# CORE_CM_CORE register map
Vendor: Texas Instruments
Peripheral module from a debugger description file (folder omap5430_ES2_PUBLIC).
Registers are 32-bit, access per field, reset 0x30000 unless marked. A register's access mark holds for its fields unless they carry their own. Offsets are as the file gives them; lines under a group give offsets from that group; [hi:lo] are bit positions; {n}, {i} and the like mark numbered series; 'fields as' and 'values as' point back to an identical list; <NAME> marks a mode.

## CORE_CM_CORE
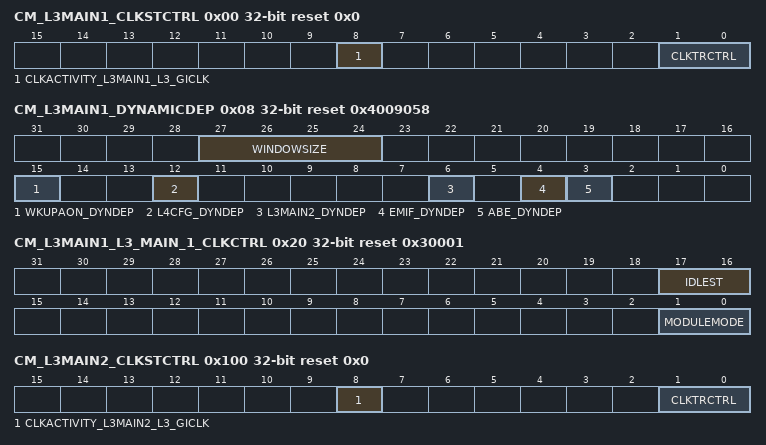
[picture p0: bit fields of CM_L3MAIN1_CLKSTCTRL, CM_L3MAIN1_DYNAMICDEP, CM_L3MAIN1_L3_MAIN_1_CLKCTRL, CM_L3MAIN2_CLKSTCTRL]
0x00 CM_L3MAIN1_CLKSTCTRL reset 0x0 — This register enables the domain power state transition. It controls the HW supervised domain power state transition between ON-ACTIVE and ON-INACTIVE states. It also holds 1 status bit per clock input of the domain.
  [8] CLKACTIVITY_L3MAIN1_L3_GICLK ro — This field indicates the state of the L3MAIN1_L3_GICLK clock in the domain. [warm reset insensitive]
    0=Inact (Corresponding clock is definitely gated); 1=Act (Corresponding clock is running or gating/ungating transition is on-going)
  [1:0] CLKTRCTRL rw — Controls the clock state transition of the L3_MAIN1 clock domain.
    0=NO_SLEEP (NO_SLEEP: Sleep transition cannot be initiated. Wakeup transition may however occur.); 3=HW_AUTO (HW_AUTO: Automatic transition is enabled. Sleep and wakeup transition are based upon hardware conditions.)
0x08 CM_L3MAIN1_DYNAMICDEP reset 0x4009058 — This register controls the dynamic domain depedencies from L3_MAIN1 domain towards 'target' domains. It is relevant only for domain having INTRCONN master port(s).
  [27:24] WINDOWSIZE rw — Size of sliding window used to monitor INTRCONN interface activity for determination of auto-sleep feature. Time unit defined byCM_DYN_DEP_PRESCAL register.
  [15] WKUPAON_DYNDEP ro — Dynamic dependency towards WKUPAON clock domain Read 1: Dependency is enabled
  [12] L4CFG_DYNDEP ro — Dynamic dependency towards L4_CFG clock domain
    1=Enabled (Dependency is enabled)
  [6] L3MAIN2_DYNDEP ro — Dynamic dependency towards L3_MAIN2 clock domain
    1=Enabled (Dependency is enabled)
  [4] EMIF_DYNDEP ro — Dynamic dependency towards EMIF clock domain
    1=Enabled (Dependency is enabled)
  [3] ABE_DYNDEP ro — Dynamic dependency towards ABE clock domain
    1=Enabled (Dependency is enabled)
0x20 CM_L3MAIN1_L3_MAIN_1_CLKCTRL ro reset 0x30001 — This register manages the L3_MAIN1 clocks.
  [17:16] IDLEST — Module idle status. [warm reset insensitive]
    0=Func (Module is fully functional, including INTRCONN); 1=Trans (Module is performing transition: wakeup, or sleep, or sleep abortion); 2=Idle (Module is in Idle mode (only INTRCONN part). It is functional if using separate functional clock); 3=Disable (Module is disabled and cannot be accessed)
  [1:0] MODULEMODE — Control the way mandatory clocks are managed.
    1=AUTO (Module is managed automatically by HW according to clock domain transition. A clock domain sleep transition put module into idle. A wakeup domain transition put it back into function. If[1:0] CLKTRCTRL = 0x3, any INTRCONN access to module is always granted. Module clocks may be gated according to the clock domain state.)
0x100 CM_L3MAIN2_CLKSTCTRL reset 0x0 — This register enables the domain power state transition. It controls the HW supervised domain power state transition between ON-ACTIVE and ON-INACTIVE states. It also holds 1 status bit per clock input of the domain.
  [8] CLKACTIVITY_L3MAIN2_L3_GICLK ro — This field indicates the state of the L3MAIN2_L3_GICLK clock in the domain. [warm reset insensitive]
    values as CM_L3MAIN1_CLKSTCTRL.CLKACTIVITY_L3MAIN1_L3_GICLK
  [1:0] CLKTRCTRL rw — Controls the clock state transition of the L3_MAIN2 clock domain.
    values as CM_L3MAIN1_CLKSTCTRL.CLKTRCTRL
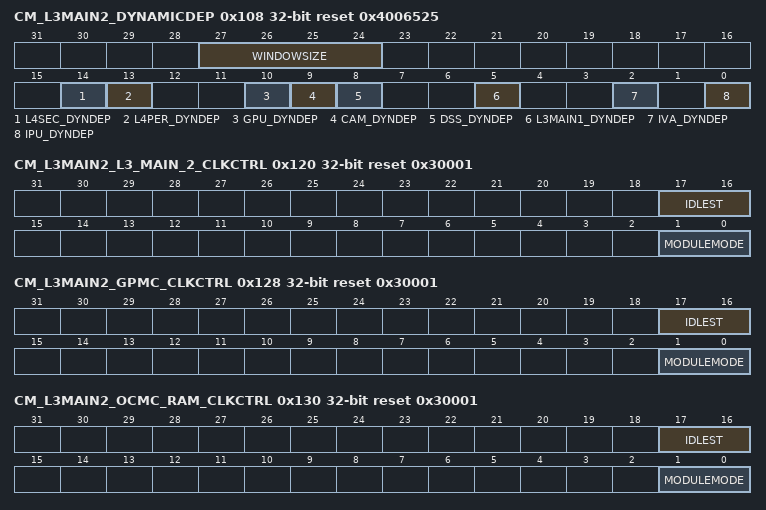
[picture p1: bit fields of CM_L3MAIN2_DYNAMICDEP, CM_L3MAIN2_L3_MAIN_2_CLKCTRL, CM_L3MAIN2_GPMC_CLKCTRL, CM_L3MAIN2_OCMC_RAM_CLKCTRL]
0x108 CM_L3MAIN2_DYNAMICDEP reset 0x4006525 — This register controls the dynamic domain dependencies from L3_MAIN2 domain towards 'target' domains. It is relevant only for domain having INTERCONN master port(s).
  [27:24] WINDOWSIZE rw — Size of sliding window used to monitor INTRCONN interface activity for determination of auto-sleep feature. Time unit defined byCM_DYN_DEP_PRESCAL register.
  [14] L4SEC_DYNDEP ro — Dynamic dependency towards L4SEC clock domain
    1=Dependency_is_enabled
  [13] L4PER_DYNDEP ro — Dynamic dependency towards L4_PER clock domain
    1=Enabled (Dependency is enabled)
  [10] GPU_DYNDEP ro — Dynamic dependency towards GPU clock domain
    1=Enabled (Dependency is enabled)
  [9] CAM_DYNDEP ro — Dynamic dependency towards CAM clock domain
    0=Disabled (Dependency is disabled)
  [8] DSS_DYNDEP ro — Dynamic dependency towards DSS clock domain
    1=Enabled (Dependency is enabled)
  [5] L3MAIN1_DYNDEP ro — Dynamic dependency towards L3_MAIN1 clock domain
    1=Enabled (Dependency is enabled)
  [2] IVA_DYNDEP ro — Dynamic dependency towards IVA clock domain
    1=Enabled (Dependency is enabled)
  [0] IPU_DYNDEP ro — Dynamic dependency towards IPU clock domain
    1=Enabled (Dependency is enabled)
0x120 CM_L3MAIN2_L3_MAIN_2_CLKCTRL ro reset 0x30001 — This register manages the L3_MAIN2 clocks.
  [17:16] IDLEST — Module idle status. [warm reset insensitive]
    values as CM_L3MAIN1_L3_MAIN_1_CLKCTRL.IDLEST
  [1:0] MODULEMODE — Control the way mandatory clocks are managed.
    1=AUTO (Module is managed automatically by HW according to clock domain transition. A clock domain sleep transition put module into idle. A wakeup domain transition put it back into function. If[1:0] CLKTRCTRL = 0x3 (HW_AUTO), any INTRCONN access to module is always granted. Module clocks may be gated according to the clock domain state.)
0x128 CM_L3MAIN2_GPMC_CLKCTRL reset 0x30001 — This register manages the GPMC clocks.
  [17:16] IDLEST ro — Module idle status. [warm reset insensitive]
    values as CM_L3MAIN1_L3_MAIN_1_CLKCTRL.IDLEST
  [1:0] MODULEMODE rw — Control the way mandatory clocks are managed.
    0=DISABLED (Module is temporarily disabled by SW. Interconnect access to module are stalled. Can be used to change timing parameter of GPMC module.); 1=RESERVED (Module is managed automatically by HW according to clock domain transition. A clock domain sleep transition put module into idle. A wakeup domain transition put it back into function. If[1:0] CLKTRCTRL = 0x3 (HW_AUTO), any INTRCONN access to module is always granted. Module clocks may be gated according to the clock domain state.)
0x130 CM_L3MAIN2_OCMC_RAM_CLKCTRL ro reset 0x30001 — This register manages the OCMC_RAM clocks.
  fields as CM_L3MAIN2_L3_MAIN_2_CLKCTRL
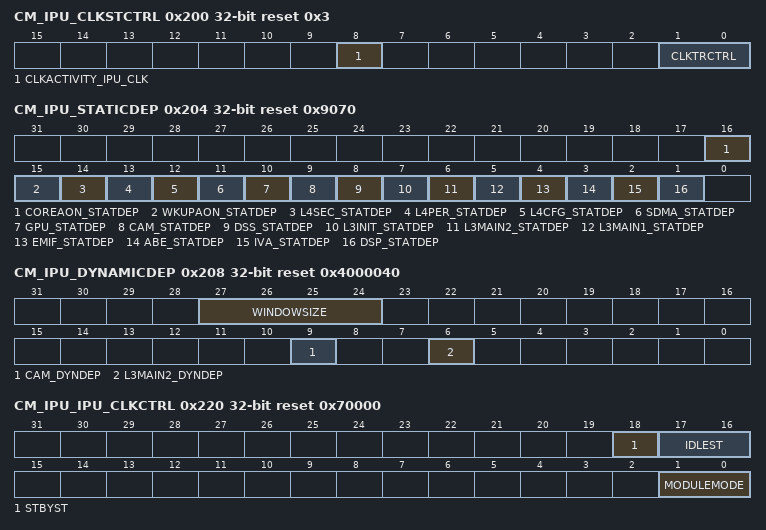
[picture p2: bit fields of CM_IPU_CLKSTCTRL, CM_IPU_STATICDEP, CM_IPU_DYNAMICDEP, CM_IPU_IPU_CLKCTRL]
0x200 CM_IPU_CLKSTCTRL reset 0x3 — This register enables the domain power state transition. It controls the HW supervised domain power state transition between ON-ACTIVE and ON-INACTIVE states. It also holds 1 status bit per clock input of the domain.
  [8] CLKACTIVITY_IPU_CLK ro — This field indicates the state of the IPU_CLK clock in the domain. [warm reset insensitive]
    0=Corresponding_clock_is_definitely_gated; 1=CLKACTIVITY_IPU_CLK_1_r (Corresponding clock is running or gating/ungating transition is on-going)
  [1:0] CLKTRCTRL rw — Controls the clock state transition of the IPU clock domain.
    0=NO_SLEEP (NO_SLEEP: Sleep transition cannot be initiated. Wakeup transition may however occur.); 1=SW_SLEEP (SW_SLEEP: Start a software forced sleep transition on the domain.); 2=SW_WKUP (SW_WKUP: Start a software forced wake-up transition on the domain.); 3=HW_AUTO (HW_AUTO: Automatic transition is enabled. Sleep and wakeup transition are based upon hardware conditions.)
0x204 CM_IPU_STATICDEP reset 0x9070 — This register controls the static domain dependencies from IPU domain towards 'target' domains. It is relevant only for domain having system initiator(s).
  [16] COREAON_STATDEP ro — Static dependency towards COREAON clock domain
    0=Disabled (Dependency is disabled)
  [15] WKUPAON_STATDEP rw — Static dependency towards WKUPAON clock domain
    0=Disabled (Dependency is disabled); 1=Enabled (Dependency is enabled)
  [14] L4SEC_STATDEP rw — Static dependency towards L4SEC clock domain
    0=Dependency_is_disabled; 1=Dependency_is_enabled
  [13] L4PER_STATDEP rw — Static dependency towards L4_PER clock domain
    values as WKUPAON_STATDEP
  [12] L4CFG_STATDEP rw — Static dependency towards L4_CFG clock domain
    values as WKUPAON_STATDEP
  [11] SDMA_STATDEP ro — Static dependency towards DMA_SYSTEM clock domain
    0=Disabled (Dependency is disabled)
  [10] GPU_STATDEP rw — Static dependency towards GPU clock domain
    values as WKUPAON_STATDEP
  [9] CAM_STATDEP ro — Static dependency towards CAM clock domain
    0=Disabled (Dependency is disabled)
  [8] DSS_STATDEP rw — Static dependency towards DSS clock domain
    values as WKUPAON_STATDEP
  [7] L3INIT_STATDEP rw — Static dependency towards L3INIT clock domain
    values as WKUPAON_STATDEP
  [6] L3MAIN2_STATDEP rw — Static dependency towards L3_MAIN2 clock domain
    values as WKUPAON_STATDEP
  [5] L3MAIN1_STATDEP rw — Static dependency towards L3_MAIN1 clock domain
    values as WKUPAON_STATDEP
  [4] EMIF_STATDEP rw — Static dependency towards EMIF clock domain
    values as WKUPAON_STATDEP
  [3] ABE_STATDEP rw — Static dependency towards ABE clock domain
    values as WKUPAON_STATDEP
  [2] IVA_STATDEP rw — Static dependency towards IVA clock domain
    values as WKUPAON_STATDEP
  [1] DSP_STATDEP rw — Static dependency towards DSP clock domain
    values as WKUPAON_STATDEP
0x208 CM_IPU_DYNAMICDEP reset 0x4000040 — This register controls the dynamic domain depedencies from IPU domain towards 'target' domains. It is relevant only for domain having INTRCONN master port(s).
  [27:24] WINDOWSIZE rw — Size of sliding window used to monitor INTRCONN interface activity for determination of auto-sleep feature. Time unit defined byCM_DYN_DEP_PRESCAL register.
  [9] CAM_DYNDEP ro — Dynamic dependency towards CAM clock domain
    0=Disabled (Dependency is disabled)
  [6] L3MAIN2_DYNDEP ro — Dynamic dependency towards L3_MAIN2 clock domain
    1=Enabled (Dependency is enabled)
0x220 CM_IPU_IPU_CLKCTRL reset 0x70000 — This register manages the IPU clocks.
  [18] STBYST ro — Module standby status. [warm reset insensitive]
    0=Func (Module is functional (not in standby)); 1=Standby (Module is in standby)
  [17:16] IDLEST ro — Module idle status. [warm reset insensitive]
    values as CM_L3MAIN1_L3_MAIN_1_CLKCTRL.IDLEST
  [1:0] MODULEMODE rw — Control the way mandatory clocks are managed.
    0=DISABLED (Module is disable by SW. Any INTRCONN access to module results in an error, except if resulting from a module wakeup (asynchronous wakeup).); 1=RESERVED (Module is managed automatically by HW according to clock domain transition. A clock domain sleep transition put module into idle. A wakeup domain transition put it back into function. If[1:0] CLKTRCTRL = 0x3 (HW_AUTO), any INTRCONN access to module is always granted. Module clocks may be gated according to the clock domain state.)
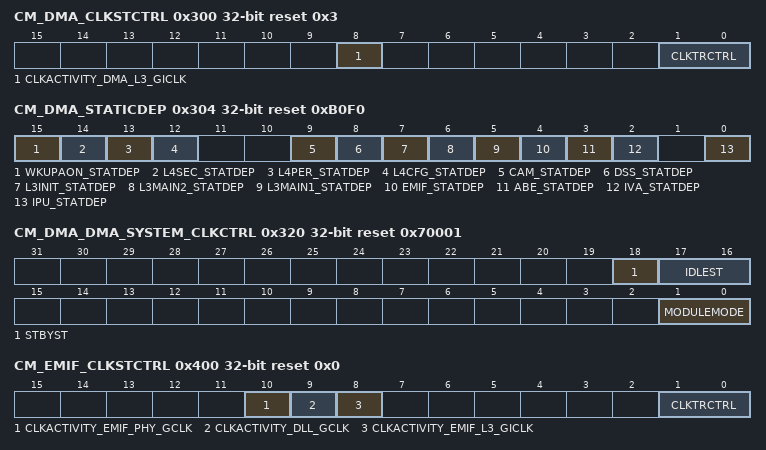
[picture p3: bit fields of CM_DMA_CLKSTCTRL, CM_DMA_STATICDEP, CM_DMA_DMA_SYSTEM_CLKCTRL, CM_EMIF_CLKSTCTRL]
0x300 CM_DMA_CLKSTCTRL reset 0x3 — This register enables the domain power state transition. It controls the HW supervised domain power state transition between ON-ACTIVE and ON-INACTIVE states. It also holds 1 status bit per clock input of the domain.
  [8] CLKACTIVITY_DMA_L3_GICLK ro — This field indicates the state of the L3_DMA_GICLK clock in the domain. [warm reset insensitive]
    values as CM_L3MAIN1_CLKSTCTRL.CLKACTIVITY_L3MAIN1_L3_GICLK
  [1:0] CLKTRCTRL rw — Controls the clock state transition of the DMA_SYSTEM clock domain.
    0=NO_SLEEP (NO_SLEEP: Sleep transition cannot be initiated. Wakeup transition may however occur.); 2=SW_WKUP (SW_WKUP: Start a software forced wake-up transition on the domain.); 3=HW_AUTO (HW_AUTO: Automatic transition is enabled. Sleep and wakeup transition are based upon hardware conditions.)
0x304 CM_DMA_STATICDEP reset 0xB0F0 — This register controls the static domain dependencies from DMA_SYSTEM domain towards 'target' domains. It is relevant only for domain having system initiator(s).
  [15] WKUPAON_STATDEP rw — Static dependency towards WKUPAON clock domain
    values as CM_IPU_STATICDEP.WKUPAON_STATDEP
  [14] L4SEC_STATDEP rw — Static dependency towards L4SEC clock domain
    0=Dependency_is_disabled; 1=Dependency_is_enabled
  [13] L4PER_STATDEP rw — Static dependency towards L4_PER clock domain
    values as CM_IPU_STATICDEP.WKUPAON_STATDEP
  [12] L4CFG_STATDEP rw — Static dependency towards L4_CFG clock domain
    values as CM_IPU_STATICDEP.WKUPAON_STATDEP
  [9] CAM_STATDEP ro — Static dependency towards CAM clock domain
    0=Disabled (Dependency is disabled)
  [8] DSS_STATDEP rw — Static dependency towards DSS clock domain
    values as CM_IPU_STATICDEP.WKUPAON_STATDEP
  [7] L3INIT_STATDEP rw — Static dependency towards L3INIT clock domain
    values as CM_IPU_STATICDEP.WKUPAON_STATDEP
  [6] L3MAIN2_STATDEP ro — Static dependency towards L3_MAIN2 clock domain
    1=Enabled (Dependency is enabled)
  [5] L3MAIN1_STATDEP rw — Static dependency towards L3_MAIN1 clock domain
    values as CM_IPU_STATICDEP.WKUPAON_STATDEP
  [4] EMIF_STATDEP rw — Static dependency towards EMIF clock domain
    values as CM_IPU_STATICDEP.WKUPAON_STATDEP
  [3] ABE_STATDEP rw — Static dependency towards ABE clock domain
    values as CM_IPU_STATICDEP.WKUPAON_STATDEP
  [2] IVA_STATDEP rw — Static dependency towards IVA clock domain
    values as CM_IPU_STATICDEP.WKUPAON_STATDEP
  [0] IPU_STATDEP rw — Static dependency towards IPU clock domain
    values as CM_IPU_STATICDEP.WKUPAON_STATDEP
0x308 CM_DMA_DYNAMICDEP ro reset 0x0 — This register controls the dynamic domain depedencies from DMA_SYSTEM domain towards 'target' domains. It is relevant only for domain having INTRCONN master port(s).
  [6] L3MAIN2_DYNDEP — Dynamic dependency towards L3_MAIN2 clock domain
    0=Disabled (Dependency is disabled)
0x320 CM_DMA_DMA_SYSTEM_CLKCTRL ro reset 0x70001 — This register manages the DMA_SYSTEM clocks.
  [18] STBYST — Module standby status. [warm reset insensitive]
    values as CM_IPU_IPU_CLKCTRL.STBYST
  [17:16] IDLEST — Module idle status. [warm reset insensitive]
    values as CM_L3MAIN1_L3_MAIN_1_CLKCTRL.IDLEST
  [1:0] MODULEMODE — Control the way mandatory clocks are managed.
    values as CM_L3MAIN2_L3_MAIN_2_CLKCTRL.MODULEMODE
0x400 CM_EMIF_CLKSTCTRL reset 0x0 — This register enables the domain power state transition. It controls the HW supervised domain power state transition between ON-ACTIVE and ON-INACTIVE states. It also hold one status bit per clock input of the domain.
  [10] CLKACTIVITY_EMIF_PHY_GCLK ro — This field indicates the state of the EMIF_PHY_GCLK clock in the domain. [warm reset insensitive]
    1=Act (Corresponding clock is running or gating/ungating transition is on-going); 0=Inact (Corresponding clock is definitely gated)
  [9] CLKACTIVITY_DLL_GCLK ro — This field indicates the state of the DLL_GCLK clock in the domain. [warm reset insensitive]
    values as CLKACTIVITY_EMIF_PHY_GCLK
  [8] CLKACTIVITY_EMIF_L3_GICLK ro — This field indicates the state of the EMIF_L3_GICLK clock in the domain. [warm reset insensitive]
    values as CLKACTIVITY_EMIF_PHY_GCLK
  [1:0] CLKTRCTRL rw — Controls the clock state transition of the EMIF clock domain.
    0=NO_SLEEP (NO_SLEEP: Sleep transition cannot be initiated. Wakeup transition may however occur.); 3=HW_AUTO (HW_AUTO: Automatic transition is enabled. Sleep and wakeup transition are based upon hardware conditions.); 2=SW_WKUP (SW_WKUP: Start a software forced wake-up transition on the domain.)
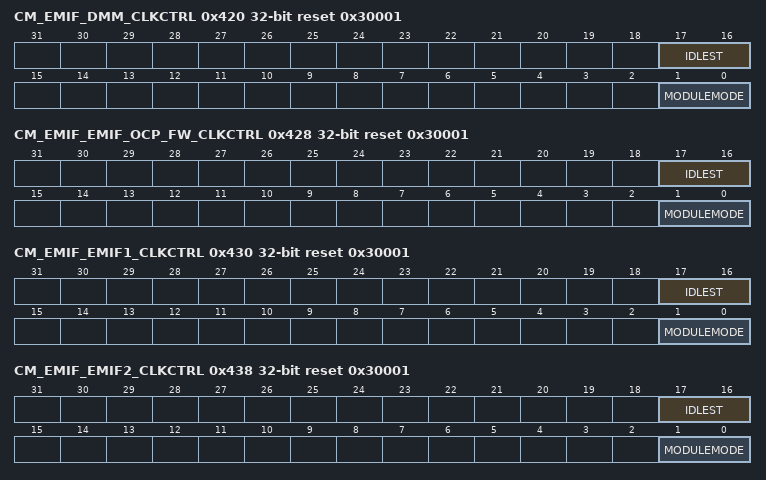
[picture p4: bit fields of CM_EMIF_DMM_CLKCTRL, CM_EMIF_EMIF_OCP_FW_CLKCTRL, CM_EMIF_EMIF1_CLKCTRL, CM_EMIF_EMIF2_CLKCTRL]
0x420 CM_EMIF_DMM_CLKCTRL ro reset 0x30001 — This register manages the DMM clocks.
  fields as CM_L3MAIN2_L3_MAIN_2_CLKCTRL
0x428 CM_EMIF_EMIF_OCP_FW_CLKCTRL ro reset 0x30001 — This register manages the EMIF_OCP_FW clocks.
  [17:16] IDLEST — Module idle status. [warm reset insensitive]
    0=INTRCONN_0 (Module is fully functional, including INTRCONN); 1=IDLEST_1_r (Module is performing transition: wakeup, or sleep, or sleep abortion); 2=INTRCONN_2 (Module is in Idle mode (only INTRCONN part). It is functional if using separate functional clock); 3=IDLEST_3_r (Module is disabled and cannot be accessed)
  [1:0] MODULEMODE — Control the way mandatory clocks are managed.
    1=HW_A_A_CLKTRCTRL_(HW_AUTO),_INTRCONN_1 (Module is managed automatically by HW according to clock domain transition. A clock domain sleep transition put module into idle. A wakeup domain transition put it back into function. If[1:0] CLKTRCTRL = 0x3 (HW_AUTO), any INTRCONN access to module is always granted. Module clocks may be gated according to the clock domain state.)
0x430 CM_EMIF_EMIF1_CLKCTRL reset 0x30001 — This register manages the EMIF1 clocks.
  [17:16] IDLEST ro — Module idle status. [warm reset insensitive]
    0=Disable (Module is fully functional, including OCP); 1=Idle (Module is performing transition: wakeup, or sleep, or sleep abortion); 2=Trans (Module is in Idle mode (only OCP part). It is functional if using separate functional clock); 3=Func (Module is disabled and cannot be accessed)
  [1:0] MODULEMODE rw — Control the way mandatory clocks are managed.
    0=DISABLED (Module is temporarily disabled by SW. OCP access to module are stalled. Can be used to change timing parameter of EMIF_1 module.); 1=AUTO (Module is managed automatically by HW according to clock domain transition. A clock domain sleep transition put module into idle. A wakeup domain transition put it back into function. If CLKTRCTRL=3, any OCP access to module is always granted. Module clocks may be gated according to the clock domain state.)
0x438 CM_EMIF_EMIF2_CLKCTRL reset 0x30001 — This register manages the EMIF2 clocks.
  [17:16] IDLEST ro — Module idle status. [warm reset insensitive]
    values as CM_L3MAIN1_L3_MAIN_1_CLKCTRL.IDLEST
  [1:0] MODULEMODE rw — Control the way mandatory clocks are managed.
    0=DISABLED (Module is temporarily disabled by SW. Interconnect access to module are stalled. Can be used to change timing parameter of EMIF2 module.); 1=RESERVED (Module is managed automatically by HW according to clock domain transition. A clock domain sleep transition put module into idle. A wakeup domain transition put it back into function. If[1:0] CLKTRCTRL = 0x3 (HW_AUTO), any INTRCONN access to module is always granted. Module clocks may be gated according to the clock domain state.)
0x440 CM_EMIF_EMIF_DLL_CLKCTRL reset 0x0 — This register manages the DLL clock.
  [8] OPTFCLKEN_DLL_CLK rw — Optional functional clock control.
    0=FCLK_DIS (Optional functional clock is disabled. DLL_CLK can be gated when EMIF domain performs sleep transition); 1=FCLK_EN (Optional functional clock is enabled. DLL_CLK is garantied to not be gated if already running.)
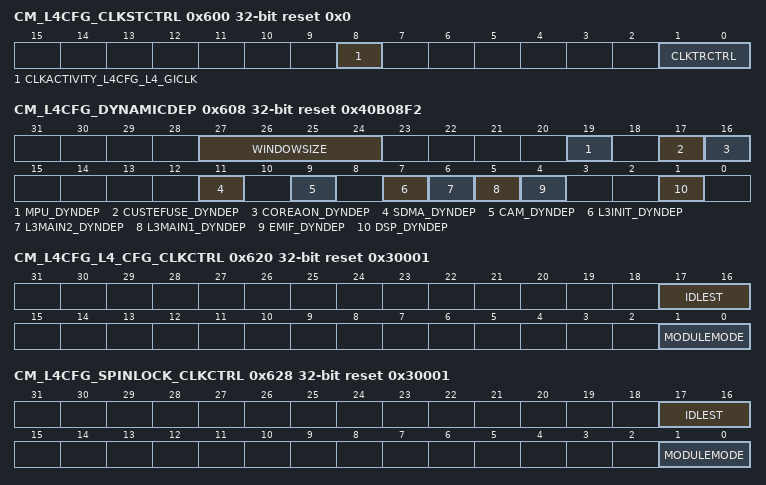
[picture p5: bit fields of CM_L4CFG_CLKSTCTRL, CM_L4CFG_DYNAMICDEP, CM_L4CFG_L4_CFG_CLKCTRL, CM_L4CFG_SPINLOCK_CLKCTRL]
0x600 CM_L4CFG_CLKSTCTRL reset 0x0 — This register enables the domain power state transition. It controls the HW supervised domain power state transition between ON-ACTIVE and ON-INACTIVE states. It also holds 1 status bit per clock input of the domain.
  [8] CLKACTIVITY_L4CFG_L4_GICLK ro — This field indicates the state of the L4CFG_L4_GICLK clock in the domain. [warm reset insensitive]
    values as CM_EMIF_CLKSTCTRL.CLKACTIVITY_EMIF_PHY_GCLK
  [1:0] CLKTRCTRL rw — Controls the clock state transition of the L4CFG clock domain.
    values as CM_L3MAIN1_CLKSTCTRL.CLKTRCTRL
0x608 CM_L4CFG_DYNAMICDEP access not given reset 0x40B08F2 — This register controls the dynamic domain depedencies from L4CFG domain towards 'target' domains. It is relevant only for domain having OCP master port(s).
  [27:24] WINDOWSIZE rw — Size of sliding window used to monitor OCP interface activity for determination of auto-sleep feature. Time unit defined byCM_DYN_DEP_PRESCAL register.
  [19] MPU_DYNDEP — Dynamic dependency towards MPU clock domain (access R Rreturns1s)
    1=Enabled (Dependency is enabled)
  [17] CUSTEFUSE_DYNDEP — Dynamic dependency towards CUSTEFUSE clock domain (access R Rreturns1s)
    1=Enabled (Dependency is enabled)
  [16] COREAON_DYNDEP — Dynamic dependency towards COREAON clock domain (access R Rreturns1s)
    1=Enabled (Dependency is enabled)
  [11] SDMA_DYNDEP — Dynamic dependency towards DMA clock domain (access R Rreturns1s)
    1=Enabled (Dependency is enabled)
  [9] CAM_DYNDEP ro — Dynamic dependency towards CAM clock domain
    0=Disabled (Dependency is disabled)
  [7] L3INIT_DYNDEP — Dynamic dependency towards L3INIT clock domain (access R Rreturns1s)
    1=Enabled (Dependency is enabled)
  [6] L3MAIN2_DYNDEP — Dynamic dependency towards L3MAIN2 clock domain (access R Rreturns1s)
    1=Enabled (Dependency is enabled)
  [5] L3MAIN1_DYNDEP — Dynamic dependency towards L3MAIN1 clock domain (access R Rreturns1s)
    1=Enabled (Dependency is enabled)
  [4] EMIF_DYNDEP — Dynamic dependency towards EMIF clock domain (access R Rreturns1s)
    1=Enabled (Dependency is enabled)
  [1] DSP_DYNDEP — Dynamic dependency towards DSP clock domain (access R Rreturns1s)
    1=Enabled (Dependency is enabled)
0x620 CM_L4CFG_L4_CFG_CLKCTRL ro reset 0x30001 — This register manages the L4_CFG clocks.
  fields as CM_L3MAIN2_L3_MAIN_2_CLKCTRL
0x628 CM_L4CFG_SPINLOCK_CLKCTRL ro reset 0x30001 — This register manages the SPINLOCK clocks.
  fields as CM_L3MAIN2_L3_MAIN_2_CLKCTRL
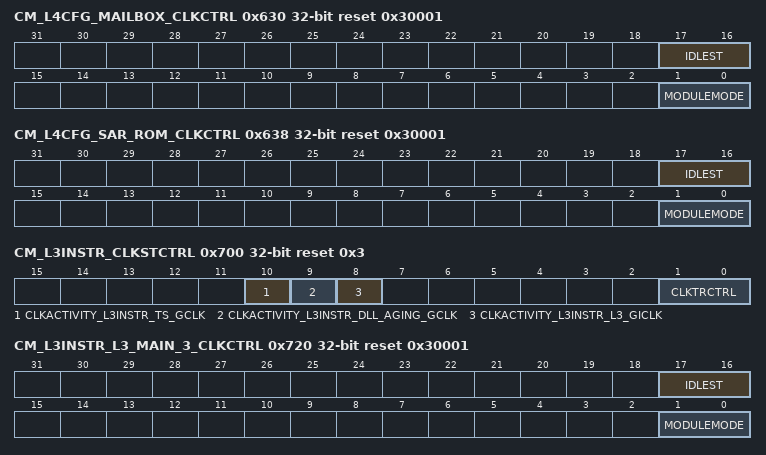
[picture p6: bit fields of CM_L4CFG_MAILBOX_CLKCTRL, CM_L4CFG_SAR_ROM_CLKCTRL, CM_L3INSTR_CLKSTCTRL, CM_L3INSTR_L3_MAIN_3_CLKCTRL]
0x630 CM_L4CFG_MAILBOX_CLKCTRL ro reset 0x30001 — This register manages the MAILBOX clocks.
  fields as CM_L3MAIN2_L3_MAIN_2_CLKCTRL
0x638 CM_L4CFG_SAR_ROM_CLKCTRL ro reset 0x30001 — This register manages the SAR_ROM clocks.
  fields as CM_L3MAIN2_L3_MAIN_2_CLKCTRL
0x700 CM_L3INSTR_CLKSTCTRL access not given reset 0x3 — This register enables the domain power state transition. It controls the HW supervised domain power state transition between ON-ACTIVE and ON-INACTIVE states. It also hold one status bit per clock input of the domain.
  [10] CLKACTIVITY_L3INSTR_TS_GCLK ro — This field indicates the state of the L3INSTR_TS_GCLK clock in the domain. [warm reset insensitive]
    values as CM_EMIF_CLKSTCTRL.CLKACTIVITY_EMIF_PHY_GCLK
  [9] CLKACTIVITY_L3INSTR_DLL_AGING_GCLK ro — This field indicates the state of the L3INSTR_DLL_AGING_GCLK clock in the domain. [warm reset insensitive]
    values as CM_EMIF_CLKSTCTRL.CLKACTIVITY_EMIF_PHY_GCLK
  [8] CLKACTIVITY_L3INSTR_L3_GICLK ro — This field indicates the state of the L3INSTR_L3_GICLK clock in the domain. [warm reset insensitive]
    values as CM_EMIF_CLKSTCTRL.CLKACTIVITY_EMIF_PHY_GCLK
  [1:0] CLKTRCTRL — Controls the clock state transition of the L3INSTR clock domain. (access R Rreturns1s)
    3=HW_AUTO (HW_AUTO: Automatic transition is enabled. Sleep and wakeup transition are based upon hardware conditions.)
0x720 CM_L3INSTR_L3_MAIN_3_CLKCTRL reset 0x30001 — This register manages the L3_MAIN3 clocks. [warm reset insensitive]
  [17:16] IDLEST ro — Module idle status.
    values as CM_L3MAIN1_L3_MAIN_1_CLKCTRL.IDLEST
  [1:0] MODULEMODE rw — Control the way mandatory clocks are managed.
    values as CM_IPU_IPU_CLKCTRL.MODULEMODE
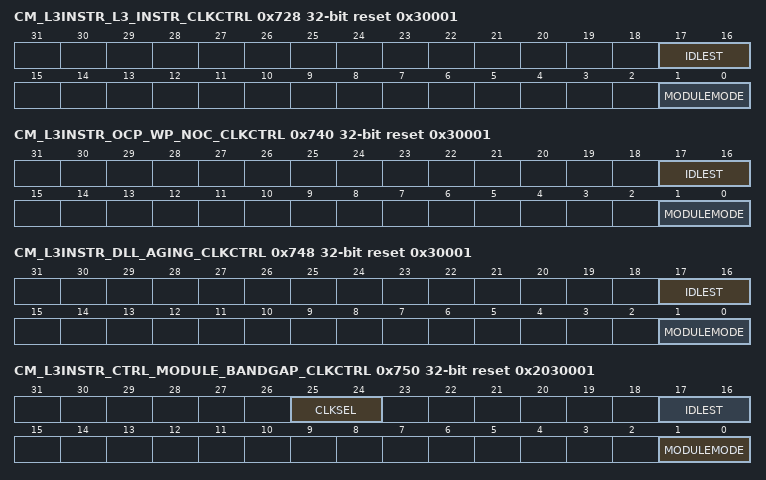
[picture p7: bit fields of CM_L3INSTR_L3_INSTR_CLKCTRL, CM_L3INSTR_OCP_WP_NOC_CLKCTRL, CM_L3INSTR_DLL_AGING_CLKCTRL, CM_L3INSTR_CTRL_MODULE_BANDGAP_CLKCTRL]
0x728 CM_L3INSTR_L3_INSTR_CLKCTRL reset 0x30001 — This register manages the L3 INSTRUMENTATION clocks. [warm reset insensitive]
  fields as CM_L3INSTR_L3_MAIN_3_CLKCTRL
0x740 CM_L3INSTR_OCP_WP_NOC_CLKCTRL reset 0x30001 — This register manages the OCP_WP_NOC clocks. [warm reset insensitive]
  [17:16] IDLEST ro — Module idle status.
    3=Disable (Module is disabled and cannot be accessed); 2=Idle (Module is in Idle mode (only Interconnect part). It is functional if using separate functional clock); 1=Trans (Module is performing transition: wakeup, or sleep, or sleep abortion); 0=Func (Module is fully functional, including Interconnect)
  [1:0] MODULEMODE rw — Control the way mandatory clocks are managed.
    0=DISABLED (Module is disable by SW. Any Interconnect access to module results in an error, except if resulting from a module wakeup (asynchronous wakeup).); 1=RESERVED (Module is managed automatically by HW according to clock domain transition. A clock domain sleep transition put module into idle. A wakeup domain transition put it back into function. If[1:0] CLKTRCTRL = 0x3 (HW_AUTO), any Interconnect access to module is always granted. Module clocks may be gated according to the clock domain state.)
0x748 CM_L3INSTR_DLL_AGING_CLKCTRL ro reset 0x30001 — This register manages the DLL_AGING clocks
  [17:16] IDLEST — Module idle status. [warm reset insensitive]
    values as CM_L3INSTR_OCP_WP_NOC_CLKCTRL.IDLEST
  [1:0] MODULEMODE — Control the way mandatory clocks are managed.
    1=AUTO (Module is managed automatically by HW according to clock domain transition. A clock domain sleep transition put module into idle. A wakeup domain transition put it back into function. If[1:0] CLKTRCTRL = 0x3 (HW_AUTO), any Interconnect access to module is always granted. Module clocks may be gated according to the clock domain state.)
0x750 CM_L3INSTR_CTRL_MODULE_BANDGAP_CLKCTRL access not given reset 0x2030001 — This register manages the CTRL_MODULE_BANDGAP clock.
  [25:24] CLKSEL rw — Selects the divider value for generating the Thermal Sensor clock from WKUPAON_ICLK source. The divider has to be selected so as to guarantee a frequency between 1MHz and 2MHz.
    0=DIV8 (Divide by 8); 1=DIV16 (Divide by 16); 2=DIV32 (Divide by 32)
  [17:16] IDLEST ro — Module idle status. [warm reset insensitive]
    3=Disable (Module is disabled and cannot be accessed); 2=Idle (Module is in Idle mode (only OCP part). It is functional if using separate functional clock); 1=Trans (Module is performing transition: wakeup, or sleep, or sleep abortion); 0=Func (Module is fully functional, including OCP)
  [1:0] MODULEMODE — Control the way mandatory clocks are managed. (access R Rreturns)
    1=AUTO (Module is managed automatically by HW according to clock domain transition. A clock domain sleep transition put module into idle. A wakeup domain transition put it back into function. If CLKTRCTRL=3, any OCP access to module is always granted. Module clocks may be gated according to the clock domain state.)
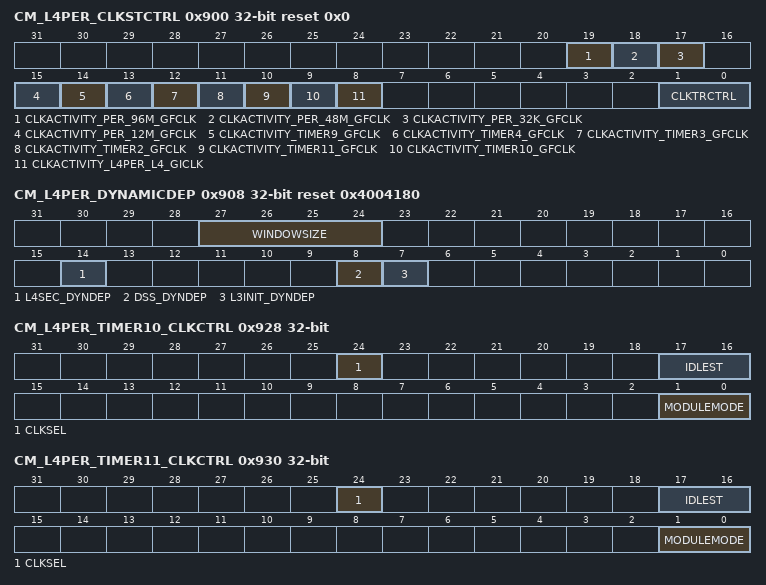
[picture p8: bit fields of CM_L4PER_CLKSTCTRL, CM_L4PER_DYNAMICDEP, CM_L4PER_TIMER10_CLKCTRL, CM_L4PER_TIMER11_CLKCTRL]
0x900 CM_L4PER_CLKSTCTRL reset 0x0 — This register enables the domain power state transition. It controls the HW supervised domain power state transition between ON-ACTIVE and ON-INACTIVE states. It also hold one status bit per clock input of the domain.
  [19] CLKACTIVITY_PER_96M_GFCLK ro — This field indicates the state of the PER_96M_GFCLK clock in the domain. [warm reset insensitive]
    values as CM_EMIF_CLKSTCTRL.CLKACTIVITY_EMIF_PHY_GCLK
  [18] CLKACTIVITY_PER_48M_GFCLK ro — This field indicates the state of the PER_48M_GFCLK clock in the domain. [warm reset insensitive]
    values as CM_EMIF_CLKSTCTRL.CLKACTIVITY_EMIF_PHY_GCLK
  [17] CLKACTIVITY_PER_32K_GFCLK ro — This field indicates the state of the PER_32K_GFCLK clock in the domain. [warm reset insensitive]
    values as CM_EMIF_CLKSTCTRL.CLKACTIVITY_EMIF_PHY_GCLK
  [15] CLKACTIVITY_PER_12M_GFCLK ro — This field indicates the state of the PER_12M_GFCLK clock in the domain. [warm reset insensitive]
    values as CM_EMIF_CLKSTCTRL.CLKACTIVITY_EMIF_PHY_GCLK
  [14] CLKACTIVITY_TIMER9_GFCLK ro — This field indicates the state of the TIMER9_GFCLK clock in the domain. [warm reset insensitive]
    values as CM_EMIF_CLKSTCTRL.CLKACTIVITY_EMIF_PHY_GCLK
  [13] CLKACTIVITY_TIMER4_GFCLK ro — This field indicates the state of the TIMER4_GFCLK clock in the domain. [warm reset insensitive]
    values as CM_EMIF_CLKSTCTRL.CLKACTIVITY_EMIF_PHY_GCLK
  [12] CLKACTIVITY_TIMER3_GFCLK ro — This field indicates the state of the TIMER3_GFCLK clock in the domain. [warm reset insensitive]
    values as CM_EMIF_CLKSTCTRL.CLKACTIVITY_EMIF_PHY_GCLK
  [11] CLKACTIVITY_TIMER2_GFCLK ro — This field indicates the state of the TIMER2_GFCLK clock in the domain. [warm reset insensitive]
    values as CM_EMIF_CLKSTCTRL.CLKACTIVITY_EMIF_PHY_GCLK
  [10] CLKACTIVITY_TIMER11_GFCLK ro — This field indicates the state of the TIMER11_GFCLK clock in the domain. [warm reset insensitive]
    values as CM_EMIF_CLKSTCTRL.CLKACTIVITY_EMIF_PHY_GCLK
  [9] CLKACTIVITY_TIMER10_GFCLK ro — This field indicates the state of the TIMER10_GFCLK clock in the domain. [warm reset insensitive]
    values as CM_EMIF_CLKSTCTRL.CLKACTIVITY_EMIF_PHY_GCLK
  [8] CLKACTIVITY_L4PER_L4_GICLK ro — This field indicates the state of the L4PER_L4_GICLK clock in the domain. [warm reset insensitive]
    values as CM_EMIF_CLKSTCTRL.CLKACTIVITY_EMIF_PHY_GCLK
  [1:0] CLKTRCTRL rw — Controls the clock state transition of the L4PER clock domain.
    0=NO_SLEEP (NO_SLEEP: Sleep transition cannot be initiated. Wakeup transition may however occur.); 1=SW_SLEEP (SW_SLEEP: Start a software forced sleep transition on the domain.); 3=HW_AUTO (HW_AUTO: Automatic transition is enabled. Sleep and wakeup transition are based upon hardware conditions.); 2=SW_WKUP (SW_WKUP: Start a software forced wake-up transition on the domain.)
0x908 CM_L4PER_DYNAMICDEP access not given reset 0x4004180 — This register controls the dynamic domain depedencies from L4PER domain towards 'target' domains. It is relevant only for domain having OCP master port(s).
  [27:24] WINDOWSIZE rw — Size of sliding window used to monitor INTERCONN interface activity for determination of auto-sleep feature. Time unit defined byCM_DYN_DEP_PRESCAL register.
  [14] L4SEC_DYNDEP — Dynamic dependency towards L4SEC clock domain (access R Rreturns1s)
    1=Enabled (Dependency is enabled)
  [8] DSS_DYNDEP — Dynamic dependency towards DSS clock domain (access R Rreturns1s)
    1=Enabled (Dependency is enabled)
  [7] L3INIT_DYNDEP — Dynamic dependency towards L3INIT clock domain (access R Rreturns1s)
    1=Enabled (Dependency is enabled)
0x928 CM_L4PER_TIMER10_CLKCTRL — This register manages the TIMER10 clocks.
  [24] CLKSEL rw — Select the source of the functional clock
    0=SEL_SYS_CLK (Selects the SYS_CLK as the source); 1=SEL_32K_CLK (Selects the 32KHz as the source)
  [17:16] IDLEST ro — Module idle status. [warm reset insensitive]
    3=Disable (Module is disabled and cannot be accessed); 2=Idle (Module is in Idle mode (only INTERCONN part). It is functional if using separate functional clock); 1=Trans (Module is performing transition: wakeup, or sleep, or sleep abortion); 0=Func (Module is fully functional, including INTERCONN)
  [1:0] MODULEMODE rw — Control the way mandatory clocks are managed.
    0=DISABLED (Module is disabled by SW. Any INTERCONN access to module results in an error, except if resulting from a module wakeup (asynchronous wakeup).); 2=ENABLE (Module is explicitly enabled. Interface clock (if not used for functions) may be gated according to the clock domain state. Functional clocks are guarantied to stay present. As long as in this configuration, power domain sleep transition cannot happen.)
0x930 CM_L4PER_TIMER11_CLKCTRL — This register manages the TIMER11 clocks.
  [24] CLKSEL rw — Select the source of the functional clock
    values as CM_L4PER_TIMER10_CLKCTRL.CLKSEL
  [17:16] IDLEST ro — Module idle status. [warm reset insensitive]
    values as CM_L3INSTR_CTRL_MODULE_BANDGAP_CLKCTRL.IDLEST
  [1:0] MODULEMODE rw — Control the way mandatory clocks are managed.
    0=DISABLED (Module is disabled by SW. Any OCP access to module results in an error, except if resulting from a module wakeup (asynchronous wakeup).); 2=ENABLE (Module is explicitly enabled. Interface clock (if not used for functions) may be gated according to the clock domain state. Functional clocks are guarantied to stay present. As long as in this configuration, power domain sleep transition cannot happen.)
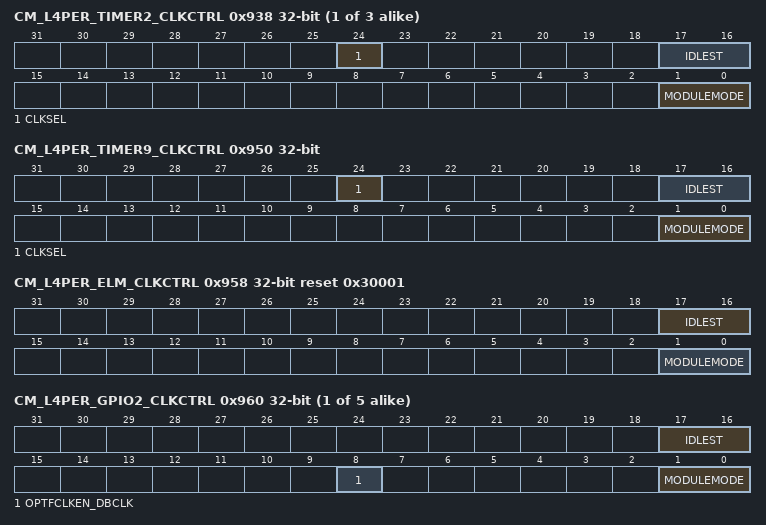
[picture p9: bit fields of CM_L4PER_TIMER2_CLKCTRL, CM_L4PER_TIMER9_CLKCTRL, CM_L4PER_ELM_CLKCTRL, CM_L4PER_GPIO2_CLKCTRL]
{0x928+8i} CM_L4PER_TIMER{i}_CLKCTRL (i=2..4) — This register manages the TIMER{i} clocks.
  fields as CM_L4PER_TIMER11_CLKCTRL
0x950 CM_L4PER_TIMER9_CLKCTRL — This register manages the TIMER9 clocks.
  fields as CM_L4PER_TIMER11_CLKCTRL
0x958 CM_L4PER_ELM_CLKCTRL access not given reset 0x30001 — This register manages the ELM clocks.
  [17:16] IDLEST ro — Module idle status. [warm reset insensitive]
    values as CM_L3INSTR_CTRL_MODULE_BANDGAP_CLKCTRL.IDLEST
  [1:0] MODULEMODE — Control the way mandatory clocks are managed. (access R Rreturns)
    values as CM_L3INSTR_CTRL_MODULE_BANDGAP_CLKCTRL.MODULEMODE
{0x950+8i} CM_L4PER_GPIO{i}_CLKCTRL (i=2..6) — This register manages the GPIO{i} clocks.
  [17:16] IDLEST ro — Module idle status. [warm reset insensitive]
    values as CM_L3INSTR_CTRL_MODULE_BANDGAP_CLKCTRL.IDLEST
  [8] OPTFCLKEN_DBCLK rw — Optional functional clock control.
    0=FCLK_DIS (Optional functional clock is disabled); 1=FCLK_EN (Optional functional clock is enabled)
  [1:0] MODULEMODE rw — Control the way mandatory clocks are managed.
    0=DISABLED (Module is disabled by SW. Any OCP access to module results in an error, except if resulting from a module wakeup (asynchronous wakeup).); 1=AUTO (Module is managed automatically by HW according to clock domain transition. A clock domain sleep transition put module into idle. A wakeup domain transition put it back into function. If CLKTRCTRL=3, any OCP access to module is always granted. Module clocks may be gated according to the clock domain state.)
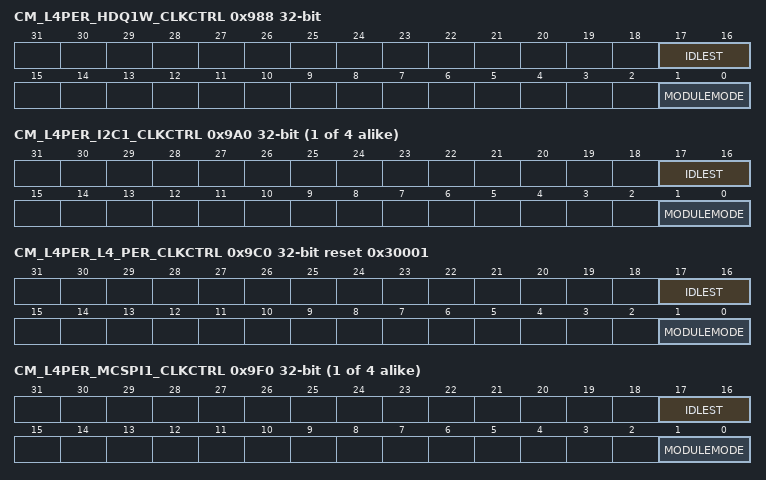
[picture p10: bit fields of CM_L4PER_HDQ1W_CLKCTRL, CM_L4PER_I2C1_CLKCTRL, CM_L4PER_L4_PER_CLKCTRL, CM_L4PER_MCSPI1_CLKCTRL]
0x988 CM_L4PER_HDQ1W_CLKCTRL — This register manages the HDQ1W clocks.
  [17:16] IDLEST ro — Module idle status. [warm reset insensitive]
    values as CM_L3INSTR_CTRL_MODULE_BANDGAP_CLKCTRL.IDLEST
  [1:0] MODULEMODE rw — Control the way mandatory clocks are managed.
    values as CM_L4PER_TIMER11_CLKCTRL.MODULEMODE
{0x998+8i} CM_L4PER_I2C{i}_CLKCTRL (i=1..4) — This register manages the I2C{i} clocks.
  fields as CM_L4PER_HDQ1W_CLKCTRL
0x9C0 CM_L4PER_L4_PER_CLKCTRL access not given reset 0x30001 — This register manages the L4_PER clocks.
  fields as CM_L4PER_ELM_CLKCTRL
{0x9E8+8i} CM_L4PER_MCSPI{i}_CLKCTRL (i=1..4) — This register manages the MCSPI{i} clocks.
  fields as CM_L4PER_HDQ1W_CLKCTRL
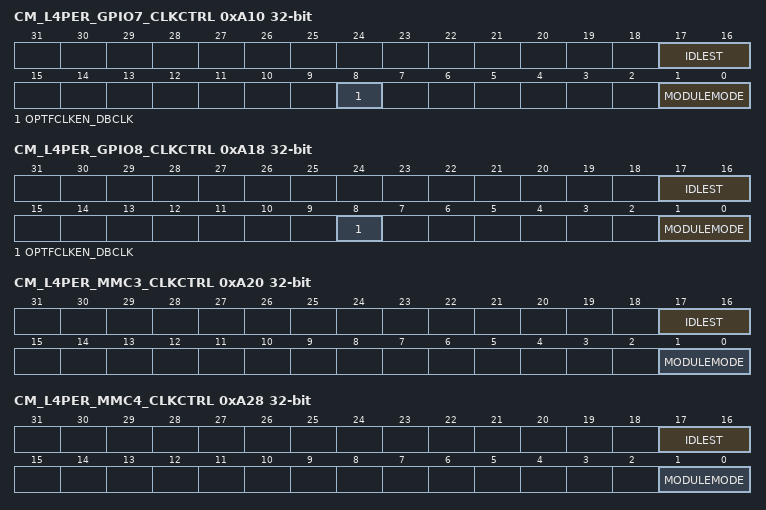
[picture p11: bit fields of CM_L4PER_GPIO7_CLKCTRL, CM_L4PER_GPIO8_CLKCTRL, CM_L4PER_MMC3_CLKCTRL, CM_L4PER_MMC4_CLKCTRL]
0xA10 CM_L4PER_GPIO7_CLKCTRL — This register manages the GPIO7 clocks.
  fields as CM_L4PER_GPIO2_CLKCTRL
0xA18 CM_L4PER_GPIO8_CLKCTRL — This register manages the GPIO8 clocks.
  fields as CM_L4PER_GPIO2_CLKCTRL
0xA20 CM_L4PER_MMC3_CLKCTRL — This register manages the MMC3 clocks.
  fields as CM_L4PER_HDQ1W_CLKCTRL
0xA28 CM_L4PER_MMC4_CLKCTRL — This register manages the MMC4 clocks.
  fields as CM_L4PER_HDQ1W_CLKCTRL
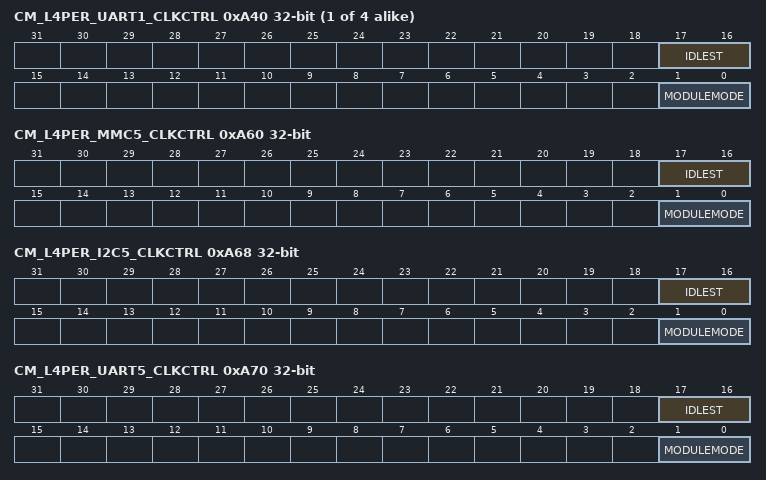
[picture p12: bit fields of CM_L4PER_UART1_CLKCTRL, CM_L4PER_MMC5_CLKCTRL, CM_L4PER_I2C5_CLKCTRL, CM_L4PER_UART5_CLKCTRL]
{0xA38+8i} CM_L4PER_UART{i}_CLKCTRL (i=1..4) — This register manages the UART{i} clocks.
  fields as CM_L4PER_HDQ1W_CLKCTRL
0xA60 CM_L4PER_MMC5_CLKCTRL — This register manages the MMC5 clocks.
  fields as CM_L4PER_HDQ1W_CLKCTRL
0xA68 CM_L4PER_I2C5_CLKCTRL — This register manages the I2C5 clocks.
  fields as CM_L4PER_HDQ1W_CLKCTRL
0xA70 CM_L4PER_UART5_CLKCTRL — This register manages the UART5 clocks.
  fields as CM_L4PER_HDQ1W_CLKCTRL
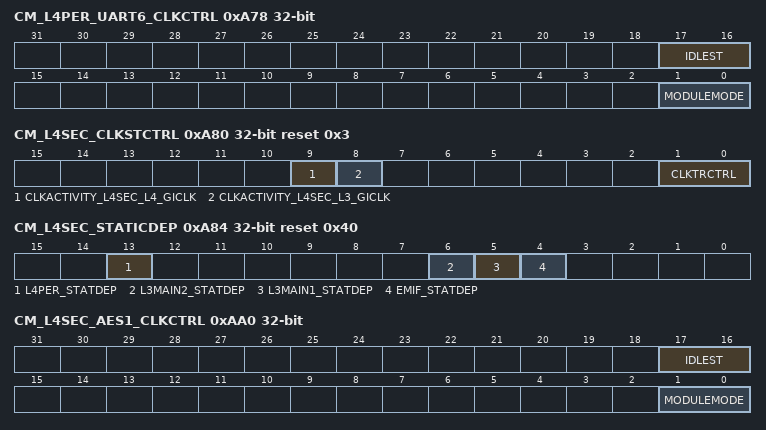
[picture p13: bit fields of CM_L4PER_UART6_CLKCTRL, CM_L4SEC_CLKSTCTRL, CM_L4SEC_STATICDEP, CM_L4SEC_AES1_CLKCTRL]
0xA78 CM_L4PER_UART6_CLKCTRL — This register manages the UART6 clocks.
  fields as CM_L4PER_HDQ1W_CLKCTRL
0xA80 CM_L4SEC_CLKSTCTRL reset 0x3 — This register enables the domain power state transition. It controls the HW supervised domain power state transition between ON-ACTIVE and ON-INACTIVE states. It also hold one status bit per clock input of the domain.
  [9] CLKACTIVITY_L4SEC_L4_GICLK ro — This field indicates the state of the L4_SECURE_GICLK clock in the domain. [warm reset insensitive]
    values as CM_EMIF_CLKSTCTRL.CLKACTIVITY_EMIF_PHY_GCLK
  [8] CLKACTIVITY_L4SEC_L3_GICLK ro — This field indicates the state of the L3_SECURE_GICLK clock in the domain. [warm reset insensitive]
    values as CM_EMIF_CLKSTCTRL.CLKACTIVITY_EMIF_PHY_GCLK
  [1:0] CLKTRCTRL rw — Controls the clock state transition of the L4SEC clock domain.
    values as CM_L4PER_CLKSTCTRL.CLKTRCTRL
0xA84 CM_L4SEC_STATICDEP access not given reset 0x40 — This register controls the static domain depedencies from L4SEC domain towards 'target' domains. It is relevant only for domain having system initiator(s).
  [13] L4PER_STATDEP rw — Static dependency towards L4PER clock domain
    values as CM_IPU_STATICDEP.WKUPAON_STATDEP
  [6] L3MAIN2_STATDEP — Static dependency towards L3MAIN2 clock domain (access R Rreturns1s)
    1=Enabled (Dependency is enabled)
  [5] L3MAIN1_STATDEP rw — Static dependency towards L3MAIN1 clock domain
    values as CM_IPU_STATICDEP.WKUPAON_STATDEP
  [4] EMIF_STATDEP rw — Static dependency towards EMIF clock domain
    values as CM_IPU_STATICDEP.WKUPAON_STATDEP
0xA88 CM_L4SEC_DYNAMICDEP ro reset 0x0 — This register controls the dynamic domain depedencies from L4SEC domain towards 'target' domains. It is relevant only for domain having OCP master port(s).
  [6] L3MAIN2_DYNDEP — Dynamic dependency towards L3MAIN2 clock domain
    0=Disabled (Dependency is disabled)
0xAA0 CM_L4SEC_AES1_CLKCTRL — This register manages the AES1 clocks.
  [17:16] IDLEST ro — Module idle status. [warm reset insensitive]
    values as CM_L3INSTR_CTRL_MODULE_BANDGAP_CLKCTRL.IDLEST
  [1:0] MODULEMODE rw — Control the way mandatory clocks are managed.
    0=DISABLED (Module is disabled by SW. Any INTERCONN access to module results in an error, except if resulting from a module wakeup (asynchronous wakeup).); 1=AUTO (Module is managed automatically by HW according to clock domain transition. A clock domain sleep transition put module into idle. A wakeup domain transition put it back into function. If CLKTRCTRL=3, any OCP access to module is always granted. Module clocks may be gated according to the clock domain state.)
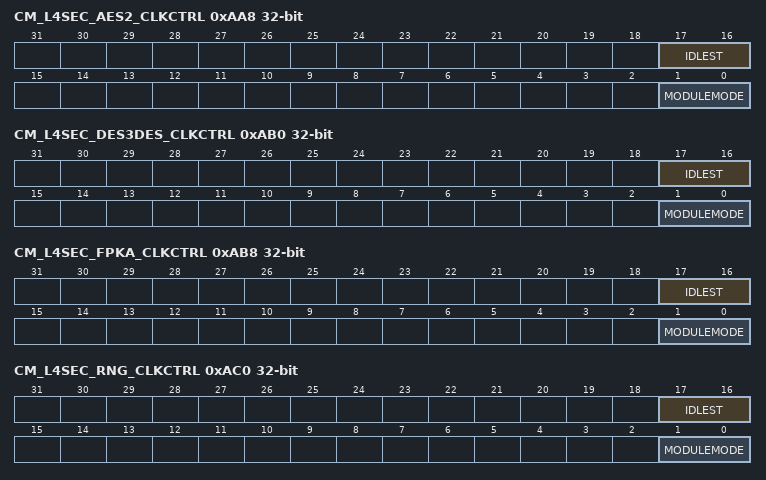
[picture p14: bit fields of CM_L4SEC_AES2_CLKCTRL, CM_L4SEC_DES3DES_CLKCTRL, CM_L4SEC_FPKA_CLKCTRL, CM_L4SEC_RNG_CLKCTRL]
0xAA8 CM_L4SEC_AES2_CLKCTRL — This register manages the AES2 clocks.
  [17:16] IDLEST ro — Module idle status. [warm reset insensitive]
    3=Disable (Module is disabled and cannot be accessed); 2=Idle (Module is in Idle mode (only OCP part). It is functional if using separate functional clock); 1=Trans (Module is performing transition: wakeup, or sleep, or sleep abortion); 0=Func (Module is fully functional, including INTERCONN)
  [1:0] MODULEMODE rw — Control the way mandatory clocks are managed.
    0=DISABLED (Module is disabled by SW. Any INTERCONN access to module results in an error, except if resulting from a module wakeup (asynchronous wakeup).); 1=AUTO (Module is managed automatically by HW according to clock domain transition. A clock domain sleep transition put module into idle. A wakeup domain transition put it back into function. If CLKTRCTRL=3, any INTERCONN access to module is always granted. Module clocks may be gated according to the clock domain state.)
0xAB0 CM_L4SEC_DES3DES_CLKCTRL — This register manages the DES3DES clocks.
  [17:16] IDLEST ro — Module idle status. [warm reset insensitive]
    values as CM_L3INSTR_CTRL_MODULE_BANDGAP_CLKCTRL.IDLEST
  [1:0] MODULEMODE rw — Control the way mandatory clocks are managed.
    values as CM_L4PER_GPIO2_CLKCTRL.MODULEMODE
0xAB8 CM_L4SEC_FPKA_CLKCTRL — This register manages the FPKA clocks.
  fields as CM_L4PER_HDQ1W_CLKCTRL
0xAC0 CM_L4SEC_RNG_CLKCTRL — This register manages the RNG clocks.
  fields as CM_L4SEC_DES3DES_CLKCTRL
0xAC8 CM_L4SEC_SHA2MD5_CLKCTRL — This register manages the SHA2MD5 clocks.
  fields as CM_L4SEC_DES3DES_CLKCTRL
0xAD8 CM_L4SEC_DMA_CRYPTO_CLKCTRL access not given reset 0x70001 — This register manages the DMA_CRYPTO clocks.
  [18] STBYST ro — Module standby status. [warm reset insensitive]
    1=Standby (Module is in standby); 0=Func (Module is functional (not in standby))
  [17:16] IDLEST ro — Module idle status. [warm reset insensitive]
    values as CM_L3INSTR_CTRL_MODULE_BANDGAP_CLKCTRL.IDLEST
  [1:0] MODULEMODE — Control the way mandatory clocks are managed. (access R Rreturns)
    values as CM_L3INSTR_CTRL_MODULE_BANDGAP_CLKCTRL.MODULEMODE
